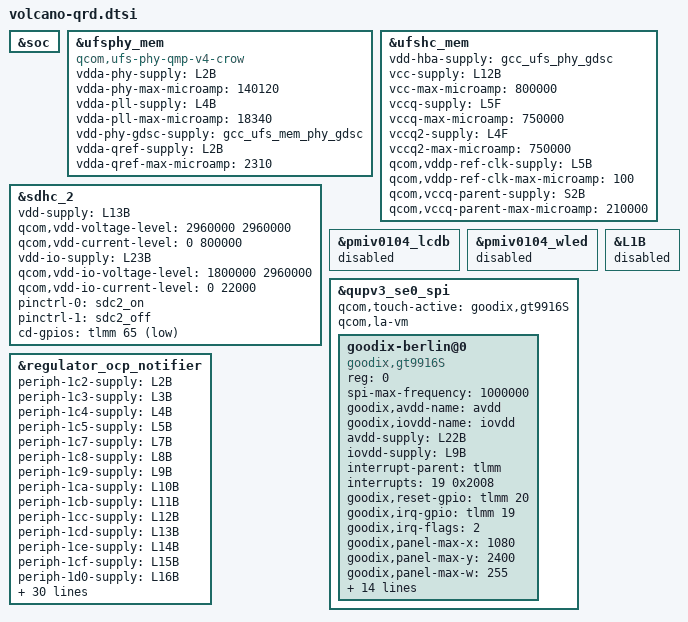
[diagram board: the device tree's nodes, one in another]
#include <dt-bindings/gpio/gpio.h>
#include "volcano-pmiv0104.dtsi"
#include "volcano-thermal-overlay.dtsi"

&soc {
};

&ufsphy_mem {
	compatible = "qcom,ufs-phy-qmp-v4-crow";

	/* VDDA_UFS_CORE */
	vdda-phy-supply = <&L2B>;
	vdda-phy-max-microamp = <140120>;

	/* VDDA_UFS_0_1P2 */
	vdda-pll-supply = <&L4B>;
	vdda-pll-max-microamp = <18340>;

	/* Phy GDSC for VDD_MX, always on */
	vdd-phy-gdsc-supply = <&gcc_ufs_mem_phy_gdsc>;

	/* Qref power supply, Refer Qref diagram */
	vdda-qref-supply = <&L2B>;
	vdda-qref-max-microamp = <2310>;

	status = "ok";
};

&ufshc_mem {
	vdd-hba-supply = <&gcc_ufs_phy_gdsc>;

	vcc-supply = <&L12B>;
	vcc-max-microamp = <800000>;

	vccq-supply = <&L5F>;
	vccq-max-microamp = <750000>;

	vccq2-supply = <&L4F>;
	vccq2-max-microamp = <750000>;

	/* VDD_PX10 is voted for the ufs_reset_n */
	qcom,vddp-ref-clk-supply = <&L5B>;
	qcom,vddp-ref-clk-max-microamp = <100>;

	qcom,vccq-parent-supply = <&S2B>;
	qcom,vccq-parent-max-microamp = <210000>;

	status = "ok";
};

&sdhc_2 {
	status = "ok";

	vdd-supply = <&L13B>;
	qcom,vdd-voltage-level = <2960000 2960000>;
	qcom,vdd-current-level = <0 800000>;

	vdd-io-supply = <&L23B>;
	qcom,vdd-io-voltage-level = <1800000 2960000>;
	qcom,vdd-io-current-level = <0 22000>;

	pinctrl-names = "default", "sleep";
	pinctrl-0 = <&sdc2_on>;
	pinctrl-1 = <&sdc2_off>;

	cd-gpios = <&tlmm 65 GPIO_ACTIVE_LOW>;
};

&pmiv0104_lcdb {
	status = "disabled";
};

&pmiv0104_wled {
	status = "disabled";
};

&qupv3_se0_spi {
	#address-cells = <1>;
	#size-cells = <0>;

	status = "ok";
	qcom,touch-active = "goodix,gt9916S";
	qcom,la-vm;

	goodix-berlin@0 {
		compatible = "goodix,gt9916S";
		reg = <0>;
		spi-max-frequency = <1000000>;
		goodix,avdd-name = "avdd";
		goodix,iovdd-name = "iovdd";
		avdd-supply = <&L22B>;
		iovdd-supply = <&L9B>;
		interrupt-parent = <&tlmm>;
		interrupts = <19 0x2008>;
		goodix,reset-gpio = <&tlmm 20 0x00>;
		goodix,irq-gpio = <&tlmm 19 0x2008>;
		goodix,irq-flags = <2>;
		goodix,panel-max-x = <1080>;
		goodix,panel-max-y = <2400>;
		goodix,panel-max-w = <255>;
		goodix,panel-max-p = <4096>;
		goodix,firmware-name = "goodix_firmware_spi.bin";
		goodix,config-name = "goodix_cfg_group_spi.bin";
		goodix,touch-type = "primary";
		goodix,qts_en;

		qts,trusted-touch-mode = "vm_mode";
		qts,touch-environment = "pvm";
		qts,trusted-touch-type = "primary";
		qts,trusted-touch-spi-irq = <598>;
		qts,trusted-touch-io-bases = <0xa80000>;
		qts,trusted-touch-io-sizes = <0x1000>;
		qts,trusted-touch-vm-gpio-list = <&tlmm 0 0 &tlmm 1 0 &tlmm 2 0
						&tlmm 3 0 &tlmm 20 0 &tlmm 19 0x2008>;
	};
};

&L1B {
	status = "disabled";
};

&regulator_ocp_notifier {
	periph-1c2-supply = <&L2B>;
	periph-1c3-supply = <&L3B>;
	periph-1c4-supply = <&L4B>;
	periph-1c5-supply = <&L5B>;
	periph-1c7-supply = <&L7B>;
	periph-1c8-supply = <&L8B>;
	periph-1c9-supply = <&L9B>;
	periph-1ca-supply = <&L10B>;
	periph-1cb-supply = <&L11B>;
	periph-1cc-supply = <&L12B>;
	periph-1cd-supply = <&L13B>;
	periph-1ce-supply = <&L14B>;
	periph-1cf-supply = <&L15B>;
	periph-1d0-supply = <&L16B>;
	periph-1d1-supply = <&L17B>;
	periph-1d2-supply = <&L18B>;
	periph-1d3-supply = <&L19B>;
	periph-1d4-supply = <&L20B>;
	periph-1d5-supply = <&L21B>;
	periph-1d6-supply = <&L22B>;
	periph-1d7-supply = <&L23B>;
	periph-19b-supply = <&S1B>;
	periph-19e-supply = <&S2B>;
	periph-1a1-supply = <&S3B>;
	periph-1a4-supply = <&S4B_LEVEL>;
	periph-1e4-supply = <&BOB>;
	periph-2c1-supply = <&L1C_LEVEL>;
	periph-2c2-supply = <&L2C>;
	periph-2c3-supply = <&L3C_LEVEL>;
	periph-2a4-supply = <&S4C_LEVEL>;
	periph-2a7-supply = <&S5C_LEVEL>;
	periph-2aa-supply = <&S6C_LEVEL>;
	periph-5c1-supply = <&L1F>;
	periph-5c2-supply = <&L2F>;
	periph-5c3-supply = <&L3F>;
	periph-5c4-supply = <&L4F>;
	periph-5c5-supply = <&L5F>;
	periph-5c6-supply = <&L6F>;
	periph-5c7-supply = <&L7F>;
	periph-5c8-supply = <&L8F>;
	periph-5c9-supply = <&L9F>;
	periph-5ca-supply = <&L10F>;
	periph-5cb-supply = <&L11F>;
	periph-5cc-supply = <&L12F_LEVEL>;
};
